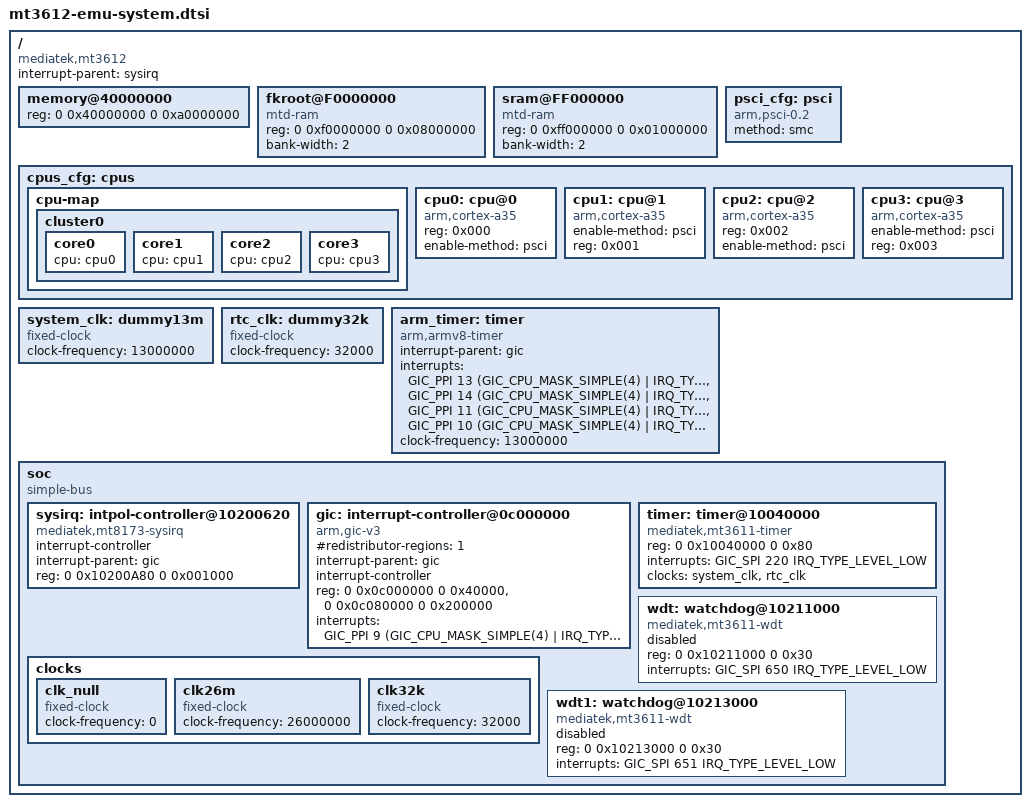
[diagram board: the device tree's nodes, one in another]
/*
 * Copyright (c) 2018 MediaTek Inc.
 * Author: Yung-Chi Chen <yung-chi.chen@mediatek.com>
 *
 * This program is free software; you can redistribute it and/or modify
 * it under the terms of the GNU General Public License version 2 as
 * published by the Free Software Foundation.
 *
 * This program is distributed in the hope that it will be useful,
 * but WITHOUT ANY WARRANTY; without even the implied warranty of
 * MERCHANTABILITY or FITNESS FOR A PARTICULAR PURPOSE.  See the
 * GNU General Public License for more details.
 */

#include <dt-bindings/interrupt-controller/arm-gic.h>

/ {
	compatible = "mediatek,mt3612";
	interrupt-parent = <&sysirq>;
	#address-cells = <2>;
	#size-cells = <2>;

	memory@40000000 {
		device_type = "memory";
		reg = <0 0x40000000 0 0xa0000000>;
	};

	fkroot@F0000000 {
		compatible = "mtd-ram";
		reg = <0 0xf0000000 0 0x08000000>;
		bank-width = <2>;
		status = "okay";
	};

	sram@FF000000 {
		compatible = "mtd-ram";
		reg = <0 0xff000000 0 0x01000000>;
		bank-width = <2>;
		status = "okay";
	};

	psci_cfg: psci {
		compatible = "arm,psci-0.2";
		method = "smc";
	};

	cpus_cfg: cpus {
		#address-cells = <1>;
		#size-cells = <0>;

		cpu-map {
			cluster0 {
				core0 {
					cpu = <&cpu0>;
				};
				core1 {
					cpu = <&cpu1>;
				};
				core2 {
					cpu = <&cpu2>;
				};
				core3 {
					cpu = <&cpu3>;
				};
			};
		};

		cpu0: cpu@0 {
			device_type = "cpu";
			compatible = "arm,cortex-a35";
			reg = <0x000>;
			enable-method = "psci";
		};

		cpu1: cpu@1 {
			device_type = "cpu";
			compatible = "arm,cortex-a35";
			enable-method = "psci";
			reg = <0x001>;
		};

		cpu2: cpu@2 {
			device_type = "cpu";
			compatible = "arm,cortex-a35";
			reg = <0x002>;
			enable-method = "psci";
		};

		cpu3: cpu@3 {
			device_type = "cpu";
			compatible = "arm,cortex-a35";
			enable-method = "psci";
			reg = <0x003>;
		};

	};

	system_clk: dummy13m {
		compatible = "fixed-clock";
		clock-frequency = <13000000>;
		#clock-cells = <0>;
	};

	rtc_clk: dummy32k {
		compatible = "fixed-clock";
		clock-frequency = <32000>;
		#clock-cells = <0>;
	};

	arm_timer: timer {
		compatible = "arm,armv8-timer";
		interrupt-parent = <&gic>;
		interrupts = <GIC_PPI 13 (GIC_CPU_MASK_SIMPLE(4) | IRQ_TYPE_LEVEL_LOW)>, /*Secure Physical Timer Event*/
			<GIC_PPI 14 (GIC_CPU_MASK_SIMPLE(4) | IRQ_TYPE_LEVEL_LOW)>, /*Non-Secure Physical Timer Event*/
			<GIC_PPI 11 (GIC_CPU_MASK_SIMPLE(4) | IRQ_TYPE_LEVEL_LOW)>, /*Virtual Timer Event*/
			<GIC_PPI 10 (GIC_CPU_MASK_SIMPLE(4) | IRQ_TYPE_LEVEL_LOW)>; /*Hypervisor Timer Event*/
			clock-frequency = <13000000>;
	};

	soc {
		#address-cells = <2>;
		#size-cells = <2>;
		compatible = "simple-bus";
		ranges;



		sysirq: intpol-controller@10200620 {
			compatible = "mediatek,mt8173-sysirq",
				     "mediatek,mt6577-sysirq";
			interrupt-controller;
			#interrupt-cells = <3>;
			interrupt-parent = <&gic>;
			reg = <0 0x10200A80 0 0x001000>;
		};

		gic: interrupt-controller@0c000000 {
			compatible = "arm,gic-v3";
			#interrupt-cells = <3>;
			#address-cells = <2>;
			#size-cells = <2>;
			#redistributor-regions = <1>;
			interrupt-parent = <&gic>;
			interrupt-controller;
			reg = <0 0x0c000000 0 0x40000>,
			      <0 0x0c080000 0 0x200000>;
			interrupts = <GIC_PPI 9 (GIC_CPU_MASK_SIMPLE(4) | IRQ_TYPE_LEVEL_HIGH)>;
		};


		clocks {
			clk_null: clk_null {
				compatible = "fixed-clock";
				#clock-cells = <0>;
				clock-frequency = <0>;
			};

			clk26m: clk26m {
				compatible = "fixed-clock";
				#clock-cells = <0>;
				clock-frequency = <26000000>;
			};

			clk32k: clk32k {
				compatible = "fixed-clock";
				#clock-cells = <0>;
				clock-frequency = <32000>;
			};
		};

		timer: timer@10040000 {
			compatible = "mediatek,mt3611-timer",
				     "mediatek,mt6577-timer";
			reg = <0 0x10040000 0 0x80>;
			interrupts = <GIC_SPI 220 IRQ_TYPE_LEVEL_LOW>;
			clocks = <&system_clk>, <&rtc_clk>;
			clock-names = "system-clk", "rtc-clk";
		};

		wdt: watchdog@10211000 {
			compatible = "mediatek,mt3611-wdt";
			reg = <0 0x10211000 0 0x30>;
			interrupts = <GIC_SPI 650 IRQ_TYPE_LEVEL_LOW>;
			status = "disabled";
		};

		wdt1: watchdog@10213000 {
			compatible = "mediatek,mt3611-wdt";
			reg = <0 0x10213000 0 0x30>;
			interrupts = <GIC_SPI 651 IRQ_TYPE_LEVEL_LOW>;
			status = "disabled";
		};
	};
};

